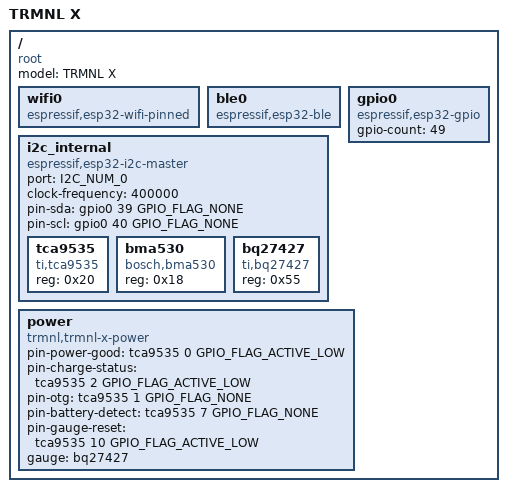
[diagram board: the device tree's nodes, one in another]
/dts-v1/;

#include <tactility/bindings/root.h>
#include <tactility/bindings/esp32_ble.h>
#include <tactility/bindings/esp32_wifi_pinned.h>
#include <tactility/bindings/esp32_gpio.h>
#include <tactility/bindings/esp32_i2c_master.h>
#include <bindings/tca95xx.h>
#include <bindings/bma530.h>
#include <bindings/bq27427.h>
#include <bindings/trmnl_x_power.h>

/ {
	compatible = "root";
	model = "TRMNL X";

	wifi0 {
		compatible = "espressif,esp32-wifi-pinned";
	};

	ble0 {
		compatible = "espressif,esp32-ble";
	};

	gpio0 {
		compatible = "espressif,esp32-gpio";
		gpio-count = <49>;
	};

	i2c_internal {
		compatible = "espressif,esp32-i2c-master";
		port = <I2C_NUM_0>;
		clock-frequency = <400000>;
		pin-sda = <&gpio0 39 GPIO_FLAG_NONE>;
		pin-scl = <&gpio0 40 GPIO_FLAG_NONE>;

		tca9535: tca9535 {
			compatible = "ti,tca9535";
			reg = <0x20>;
		};

		bma530: bma530 {
			compatible = "bosch,bma530";
			reg = <0x18>;
		};

		bq27427: bq27427 {
			compatible = "ti,bq27427";
			reg = <0x55>;
		};
	};

	power {
		compatible = "trmnl,trmnl-x-power";
		pin-power-good = <&tca9535 0 GPIO_FLAG_ACTIVE_LOW>;
		pin-charge-status = <&tca9535 2 GPIO_FLAG_ACTIVE_LOW>;
		pin-otg = <&tca9535 1 GPIO_FLAG_NONE>;
		pin-battery-detect = <&tca9535 7 GPIO_FLAG_NONE>;
		pin-gauge-reset = <&tca9535 10 GPIO_FLAG_ACTIVE_LOW>;
		gauge = <&bq27427>;
	};
};
